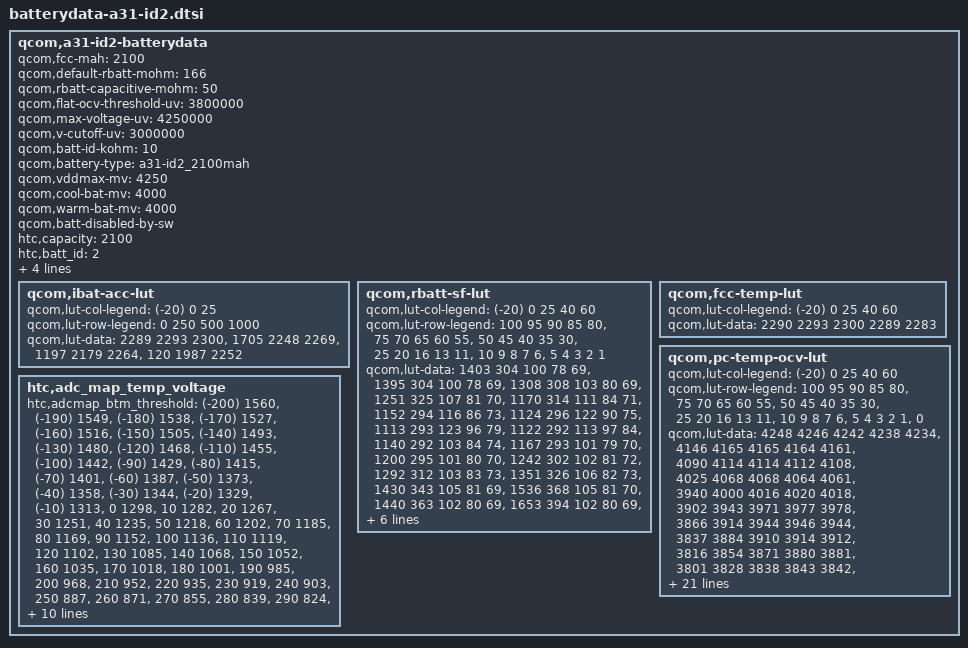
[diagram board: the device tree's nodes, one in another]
/* Copyright (c) 2013, The Linux Foundation. All rights reserved.
 *
 * This program is free software; you can redistribute it and/or modify
 * it under the terms of the GNU General Public License version 2 and
 * only version 2 as published by the Free Software Foundation.
 *
 * This program is distributed in the hope that it will be useful,
 * but WITHOUT ANY WARRANTY; without even the implied warranty of
 * MERCHANTABILITY or FITNESS FOR A PARTICULAR PURPOSE.  See the
 * GNU General Public License for more details.
 * VEKEN battery
 */

qcom,a31-id2-batterydata {
	qcom,fcc-mah = <2100>;
	qcom,default-rbatt-mohm = <166>;
	qcom,rbatt-capacitive-mohm = <50>;
	qcom,flat-ocv-threshold-uv = <3800000>;
	qcom,max-voltage-uv = <4250000>;
	qcom,v-cutoff-uv = <3000000>;
	qcom,batt-id-kohm = <10>;
	qcom,battery-type = "a31-id2_2100mah";
	qcom,vddmax-mv = <4250>;
	qcom,cool-bat-mv = <4000>;
	qcom,warm-bat-mv = <4000>;
	qcom,batt-disabled-by-sw;
	htc,capacity = <2100>;
	htc,batt_id = <2>;
	htc,id_raw_min = <2>;
	htc,id_raw_max = <2>;
	htc,type = <2>;
	htc,model_name = "B0PE6100";

	qcom,ibat-acc-lut {
		qcom,lut-col-legend = <(-20) 0 25>;
		qcom,lut-row-legend = <0 250 500 1000>;
		qcom,lut-data = <2289 2293 2300>,
				<1705 2248 2269>,
				<1197 2179 2264>,
				<120 1987 2252>;
	};

	qcom,rbatt-sf-lut {
		qcom,lut-col-legend = <(-20) 0 25 40 60>;
		qcom,lut-row-legend = <100 95 90 85 80>,
				<75 70 65 60 55>,
				<50 45 40 35 30>,
				<25 20 16 13 11>,
				<10 9 8 7 6>,
				<5 4 3 2 1>;
		qcom,lut-data = <1403 304 100 78 69>,
				<1395 304 100 78 69>,
				<1308 308 103 80 69>,
				<1251 325 107 81 70>,
				<1170 314 111 84 71>,
				<1152 294 116 86 73>,
				<1124 296 122 90 75>,
				<1113 293 123 96 79>,
				<1122 292 113 97 84>,
				<1140 292 103 84 74>,
				<1167 293 101 79 70>,
				<1200 295 101 80 70>,
				<1242 302 102 81 72>,
				<1292 312 103 83 73>,
				<1351 326 106 82 73>,
				<1430 343 105 81 69>,
				<1536 368 105 81 70>,
				<1440 363 102 80 69>,
				<1653 394 102 80 69>,
				<1987 410 102 79 69>,
				<2193 425 104 81 71>,
				<2405 441 106 82 72>,
				<2631 460 110 84 74>,
				<2919 479 114 86 77>,
				<3289 501 117 89 75>,
				<3698 524 115 83 72>,
				<4431 561 116 84 72>,
				<5501 624 123 88 75>,
				<7681 718 135 96 82>,
				<15362 1223 172 125 109>;
	};

	qcom,fcc-temp-lut {
		qcom,lut-col-legend = <(-20) 0 25 40 60>;
		qcom,lut-data = <2290 2293 2300 2289 2283>;
	};

	qcom,pc-temp-ocv-lut {
		qcom,lut-col-legend = <(-20) 0 25 40 60>;
		qcom,lut-row-legend = <100 95 90 85 80>,
				<75 70 65 60 55>,
				<50 45 40 35 30>,
				<25 20 16 13 11>,
				<10 9 8 7 6>,
				<5 4 3 2 1>,
				<0>;
		qcom,lut-data = <4248 4246 4242 4238 4234>,
				<4146 4165 4165 4164 4161>,
				<4090 4114 4114 4112 4108>,
				<4025 4068 4068 4064 4061>,
				<3940 4000 4016 4020 4018>,
				<3902 3943 3971 3977 3978>,
				<3866 3914 3944 3946 3944>,
				<3837 3884 3910 3914 3912>,
				<3816 3854 3871 3880 3881>,
				<3801 3828 3838 3843 3842>,
				<3788 3807 3816 3816 3815>,
				<3775 3789 3798 3800 3797>,
				<3763 3778 3786 3786 3784>,
				<3749 3767 3775 3774 3772>,
				<3735 3754 3767 3764 3759>,
				<3718 3740 3756 3750 3736>,
				<3698 3726 3740 3732 3718>,
				<3678 3716 3720 3712 3698>,
				<3656 3706 3699 3692 3678>,
				<3635 3698 3690 3682 3670>,
				<3624 3696 3688 3682 3670>,
				<3611 3691 3687 3680 3668>,
				<3596 3684 3686 3679 3667>,
				<3579 3676 3682 3676 3664>,
				<3558 3660 3673 3670 3652>,
				<3534 3636 3646 3644 3620>,
				<3498 3596 3599 3596 3572>,
				<3452 3538 3535 3535 3512>,
				<3386 3454 3448 3454 3432>,
				<3270 3312 3316 3328 3308>,
				<3000 3000 3000 3000 3000>;
	};

	htc,adc_map_temp_voltage {
		htc,adcmap_btm_threshold = <(-200) 1560>,
								<(-190) 1549>,
								<(-180) 1538>,
								<(-170) 1527>,
								<(-160) 1516>,
								<(-150) 1505>,
								<(-140) 1493>,
								<(-130) 1480>,
								<(-120) 1468>,
								<(-110) 1455>,
								<(-100) 1442>,
								<(-90) 1429>,
								<(-80) 1415>,
								<(-70) 1401>,
								<(-60) 1387>,
								<(-50) 1373>,
								<(-40) 1358>,
								<(-30) 1344>,
								<(-20) 1329>,
								<(-10) 1313>,
								<0 1298>,
								<10 1282>,
								<20 1267>,
								<30 1251>,
								<40 1235>,
								<50 1218>,
								<60 1202>,
								<70 1185>,
								<80 1169>,
								<90 1152>,
								<100 1136>,
								<110 1119>,
								<120 1102>,
								<130 1085>,
								<140 1068>,
								<150 1052>,
								<160 1035>,
								<170 1018>,
								<180 1001>,
								<190 985>,
								<200 968>,
								<210 952>,
								<220 935>,
								<230 919>,
								<240 903>,
								<250 887>,
								<260 871>,
								<270 855>,
								<280 839>,
								<290 824>,
								<300 809>,
								<310 794>,
								<320 779>,
								<330 764>,
								<340 750>,
								<350 735>,
								<360 721>,
								<370 707>,
								<380 694>,
								<390 680>,
								<400 667>,
								<410 654>,
								<420 641>,
								<430 629>,
								<440 616>,
								<450 604>,
								<460 593>,
								<470 581>,
								<480 570>,
								<490 559>,
								<500 548>,
								<510 537>,
								<520 527>,
								<530 516>,
								<540 506>,
								<550 497>,
								<560 487>,
								<570 478>,
								<580 469>,
								<590 460>,
								<600 451>,
								<610 442>,
								<620 434>,
								<630 426>,
								<640 418>,
								<650 410>,
								<660 403>,
								<670 396>,
								<680 388>,
								<690 381>,
								<700 375>,
								<710 368>,
								<720 362>,
								<730 355>,
								<740 349>,
								<750 343>,
								<760 337>,
								<770 332>,
								<780 326>,
								<790 321>;
	};
};
